AUTOSAR XML (schema 4-2-2)
package /ASW_DCM
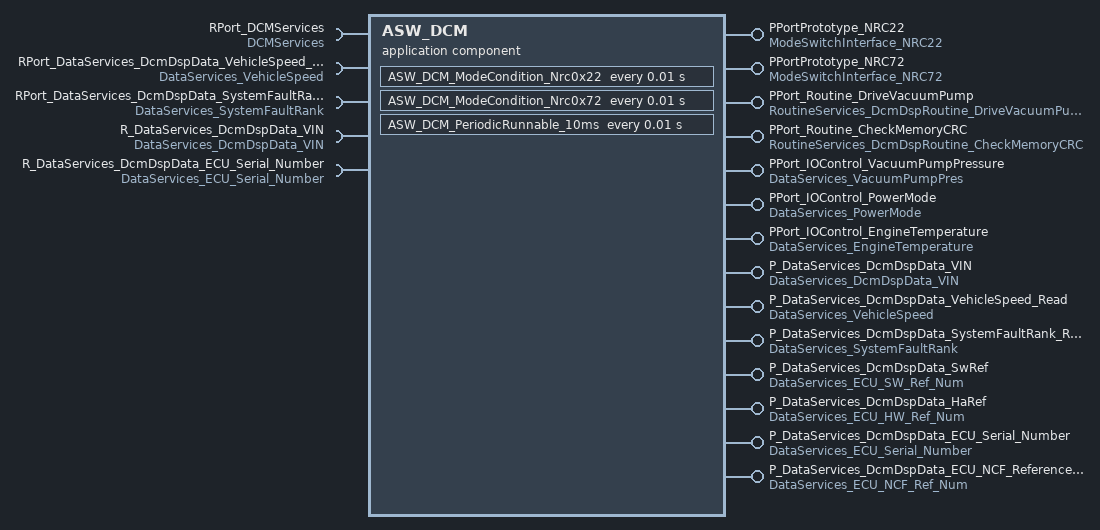
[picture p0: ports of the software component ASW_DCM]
  application sw component type ASW_DCM
    provide port PPortPrototype_NRC22: provided-interface=ModeSwitchInterface_NRC22
    provide port PPortPrototype_NRC72: provided-interface=ModeSwitchInterface_NRC72
    5 x require port:
      RPort_DCMServices: required-interface=DCMServices
      RPort_DataServices_DcmDspData_VehicleSpeed_Write: required-interface=DataServices_VehicleSpeed
      RPort_DataServices_DcmDspData_SystemFaultRank_Write: required-interface=DataServices_SystemFaultRank
      R_DataServices_DcmDspData_VIN: required-interface=DataServices_DcmDspData_VIN
      R_DataServices_DcmDspData_ECU_Serial_Number: required-interface=DataServices_ECU_Serial_Number
    12 x provide port:
      PPort_Routine_DriveVacuumPump: provided-interface=RoutineServices_DcmDspRoutine_DriveVacuumPump
      PPort_Routine_CheckMemoryCRC: provided-interface=RoutineServices_DcmDspRoutine_CheckMemoryCRC
      PPort_IOControl_VacuumPumpPressure: provided-interface=DataServices_VacuumPumpPres
      PPort_IOControl_PowerMode: provided-interface=DataServices_PowerMode
      PPort_IOControl_EngineTemperature: provided-interface=DataServices_EngineTemperature
      P_DataServices_DcmDspData_VIN: provided-interface=DataServices_DcmDspData_VIN
      P_DataServices_DcmDspData_VehicleSpeed_Read: provided-interface=DataServices_VehicleSpeed
      P_DataServices_DcmDspData_SystemFaultRank_Read: provided-interface=DataServices_SystemFaultRank
      P_DataServices_DcmDspData_SwRef: provided-interface=DataServices_ECU_SW_Ref_Num
      P_DataServices_DcmDspData_HaRef: provided-interface=DataServices_ECU_HW_Ref_Num
      P_DataServices_DcmDspData_ECU_Serial_Number: provided-interface=DataServices_ECU_Serial_Number
      P_DataServices_DcmDspData_ECU_NCF_Reference_Number: provided-interface=DataServices_ECU_NCF_Ref_Num
    behavior IB_Diag_SWC: data-type-mapping=[DTS_DcmDiagnosticSessionControl, ComMModeMapping, DTS_DcmEcuReset, DataTypeMappingSet_NRC72, DataTypeMappingSet_NRC22, DTS_DcmDspDid_DcmDspData_VIN, DTS_DcmDspDid_ECU_SW_Ref_Num, DTS_DcmDspDid_ECU_HW_Ref_Num, DTS_DcmDspDid_ECU_NCF_Ref_Num, DTS_DcmDspDid_ECU_Serial_Number]
      timing event TE_ModeControl_NRC22: start-on-event=ASW_DCM_ModeCondition_Nrc0x22, period=0.01
      timing event TE_ModeControl_NRC72: start-on-event=ASW_DCM_ModeCondition_Nrc0x72, period=0.01
      timing event TE_ASW_DCM: start-on-event=ASW_DCM_PeriodicRunnable_10ms, period=0.01
      21 x operation invoked event:
        OIE_IOControl_EngineTemperature_ReadData: start-on-event=ASW_DCM_IOControl_EngineTemperature_ReadData, operation=PPort_IOControl_EngineTemperature.ReadData
        OIE_IOControl_EngineTemperature_returnControlToECU: start-on-event=ASW_DCM_IOControl_EngineTemperature_returnControlToECU, operation=PPort_IOControl_EngineTemperature.ReturnControlToECU
        OIE_IOControl_EngineTemperature_resetToDefault: start-on-event=ASW_DCM_IOControl_EngineTemperature_resetToDefault, operation=PPort_IOControl_EngineTemperature.ResetToDefault
        OIE_IOControl_EngineTemperature_freezeCurrentState: start-on-event=ASW_DCM_IOControl_EngineTemperature_freezeCurrentState, operation=PPort_IOControl_EngineTemperature.FreezeCurrentState
        OIE_IOControl_EngineTemperature_shortTermAdjustment: start-on-event=ASW_DCM_IOControl_EngineTemperature_shortTermAdjustment, operation=PPort_IOControl_EngineTemperature.ShortTermAdjustment
        OIE_RoutineServices_CheckMemoryCRC_Start: start-on-event=ASW_DCM_RoutineServices_CheckMemoryCRC_Start, operation=PPort_Routine_CheckMemoryCRC.Start
        OIE_RoutineServices_CheckMemoryCRC_Stop: start-on-event=ASW_DCM_RoutineServices_CheckMemoryCRC_Stop, operation=PPort_Routine_CheckMemoryCRC.Stop
        OIE_RoutineServices_CheckMemoryCRC_RequestRoutineResults: start-on-event=ASW_DCM_RoutineServices_CheckMemoryCRC_RequestRoutineResults, operation=PPort_Routine_CheckMemoryCRC.RequestResults
        OIE_IOControl_PowerMode_ReadData: start-on-event=ASW_DCM_IOControl_PoweMode_ReadData, operation=PPort_IOControl_PowerMode.ReadData
        OIE_IOControl_PowerMode_returnControlToECU: start-on-event=ASW_DCM_IOControl_PowerMode_returnControlToECU, operation=PPort_IOControl_PowerMode.ReturnControlToECU
        OIE_IOControl_PowerMode_resetToDefault: start-on-event=ASW_DCM_IOControl_PowerMode_resetToDefault, operation=PPort_IOControl_PowerMode.ResetToDefault
        OIE_IOControl_PowerMode_freezeCurrentState: start-on-event=ASW_DCM_IOControl_PowerMode_freezeCurrentState, operation=PPort_IOControl_PowerMode.FreezeCurrentState
        OIE_IOControl_PowerMode_shortTermAdjustment: start-on-event=ASW_DCM_IOControl_PowerMode_shortTermAdjustment, operation=PPort_IOControl_PowerMode.ShortTermAdjustment
        OIE_RoutineServices_DriveVacuumPump_Start: start-on-event=ASW_DCM_RoutineServices_DriveVacuumPump_Start, operation=PPort_Routine_DriveVacuumPump.Start
        OIE_RoutineServices_DriveVacuumPump_Stop: start-on-event=ASW_DCM_RoutineServices_DriveVacuumPump_Stop, operation=PPort_Routine_DriveVacuumPump.Stop
        OIE_RoutineServices_DriveVacuumPump_RequestRoutineResults: start-on-event=ASW_DCM_RoutineServices_DriveVacuumPump_RequestRoutineResults, operation=PPort_Routine_DriveVacuumPump.RequestResults
        OIE_IOControl_VacuumPumpPressure_ReadData: start-on-event=ASW_DCM_IOControl_VacuumPumpPressure_ReadData, operation=PPort_IOControl_VacuumPumpPressure.ReadData
        OIE_IOControl_VacuumPumpPressure_returnControlToECU: start-on-event=ASW_DCM_IOControl_VacuumPumpPressure_returnControlToECU, operation=PPort_IOControl_VacuumPumpPressure.ReturnControlToECU
        OIE_IOControl_VacuumPumpPressure_resetToDefault: start-on-event=ASW_DCM_IOControl_VacuumPumpPressure_resetToDefault, operation=PPort_IOControl_VacuumPumpPressure.ResetToDefault
        OIE_IOControl_VacuumPumpPressure_freezeCurrentState: start-on-event=ASW_DCM_IOControl_VacuumPumpPressure_freezeCurrentState, operation=PPort_IOControl_VacuumPumpPressure.FreezeCurrentState
        OIE_IOControl_VacuumPumpPressure_shortTermAdjustment: start-on-event=ASW_DCM_IOControl_VacuumPumpPressure_shortTermAdjustment, operation=PPort_IOControl_VacuumPumpPressure.ShortTermAdjustment
      24 x runnable:
        ASW_DCM_ModeCondition_Nrc0x22: mode-access-point=PPortPrototype_NRC22.MDGP_ModeDeclarationGroup_NRC22, symbol=ASW_DCM_ModeCondition_Nrc0x22_func
          mode switch point ModeSwitchPoint_0: mode-group=PPortPrototype_NRC22.MDGP_ModeDeclarationGroup_NRC22
        ASW_DCM_ModeCondition_Nrc0x72: mode-access-point=PPortPrototype_NRC72.MDGP_ModeDeclarationGroup_NRC72, symbol=ASW_DCM_ModeCondition_Nrc0x72_func
          mode switch point ModeSwitchPoint_0: mode-group=PPortPrototype_NRC72.MDGP_ModeDeclarationGroup_NRC72
        ASW_DCM_PeriodicRunnable_10ms: symbol=ASW_DCM_PeriodicRunnable_10ms_func
          data-receive-point-by-arguments:
            4 x access:
              DRPA_Data_0: accessed-variable=RPort_DataServices_DcmDspData_SystemFaultRank_Write.Data
              DRPA_Data_1: accessed-variable=RPort_DataServices_DcmDspData_VehicleSpeed_Write.Data
              DRPA_Data_2: accessed-variable=R_DataServices_DcmDspData_ECU_Serial_Number.Data
              DRPA_Data_3: accessed-variable=R_DataServices_DcmDspData_VIN.Data
          data-send-points:
            7 x access:
              DSP_Data_0: accessed-variable=P_DataServices_DcmDspData_ECU_Serial_Number.Data
              DSP_Data_1: accessed-variable=P_DataServices_DcmDspData_VehicleSpeed_Read.Data
              DSP_Data_2: accessed-variable=P_DataServices_DcmDspData_VIN.Data
              DSP_Data_3: accessed-variable=P_DataServices_DcmDspData_HaRef.Data
              DSP_Data_4: accessed-variable=P_DataServices_DcmDspData_SwRef.Data
              DSP_Data_5: accessed-variable=P_DataServices_DcmDspData_SystemFaultRank_Read.Data
              DSP_Data_6: accessed-variable=P_DataServices_DcmDspData_ECU_NCF_Reference_Number.Data
        ASW_DCM_IOControl_VacuumPumpPressure_returnControlToECU: symbol=ASW_DCM_IOControl_VacuumPumpPressure_returnControlToECU_func
        ASW_DCM_IOControl_VacuumPumpPressure_resetToDefault: symbol=ASW_DCM_IOControl_VacuumPumpPressure_resetToDefault_func
        ASW_DCM_IOControl_VacuumPumpPressure_freezeCurrentState: symbol=ASW_DCM_IOControl_VacuumPumpPressure_freezeCurrentState_func
        ASW_DCM_IOControl_VacuumPumpPressure_shortTermAdjustment: symbol=ASW_DCM_IOControl_VacuumPumpPressure_shortTermAdjustment_func
        ASW_DCM_IOControl_VacuumPumpPressure_ReadData: symbol=ASW_DCM_IOControl_VacuumPumpPressure_ReadData_func
        ASW_DCM_RoutineServices_DriveVacuumPump_Start: symbol=ASW_DCM_RoutineServices_DriveVacuumPump_Start_func
        ASW_DCM_RoutineServices_DriveVacuumPump_Stop: symbol=ASW_DCM_RoutineServices_DriveVacuumPump_Stop_func
        ASW_DCM_RoutineServices_DriveVacuumPump_RequestRoutineResults: symbol=ASW_DCM_RoutineServices_DriveVacuumPump_RequestRoutineResults_func
        ASW_DCM_IOControl_EngineTemperature_freezeCurrentState: symbol=ASW_DCM_IOControl_EngineTemperature_freezeCurrentState_func
        ASW_DCM_IOControl_EngineTemperature_ReadData: symbol=ASW_DCM_IOControl_EngineTemperature_ReadData_func
        ASW_DCM_IOControl_EngineTemperature_resetToDefault: symbol=ASW_DCM_IOControl_EngineTemperature_resetToDefault_func
        ASW_DCM_IOControl_EngineTemperature_returnControlToECU: symbol=ASW_DCM_IOControl_EngineTemperature_returnControlToECU_func
        ASW_DCM_IOControl_EngineTemperature_shortTermAdjustment: symbol=ASW_DCM_IOControl_EngineTemperature_shortTermAdjustment_func
        ASW_DCM_IOControl_PoweMode_ReadData: symbol=ASW_DCM_IOControl_PoweMode_ReadData_func
        ASW_DCM_IOControl_PowerMode_freezeCurrentState: symbol=ASW_DCM_IOControl_PowerMode_freezeCurrentState_func
        ASW_DCM_IOControl_PowerMode_resetToDefault: symbol=ASW_DCM_IOControl_PowerMode_resetToDefault_func
        ASW_DCM_IOControl_PowerMode_returnControlToECU: symbol=ASW_DCM_IOControl_PowerMode_returnControlToECU_func
        ASW_DCM_IOControl_PowerMode_shortTermAdjustment: symbol=ASW_DCM_IOControl_PowerMode_shortTermAdjustment_func
        ASW_DCM_RoutineServices_CheckMemoryCRC_RequestRoutineResults: symbol=ASW_DCM_RoutineServices_CheckMemoryCRC_RequestRoutineResults_func
        ASW_DCM_RoutineServices_CheckMemoryCRC_Start: symbol=ASW_DCM_RoutineServices_CheckMemoryCRC_Start_func
        ASW_DCM_RoutineServices_CheckMemoryCRC_Stop: symbol=ASW_DCM_RoutineServices_CheckMemoryCRC_Stop_func
